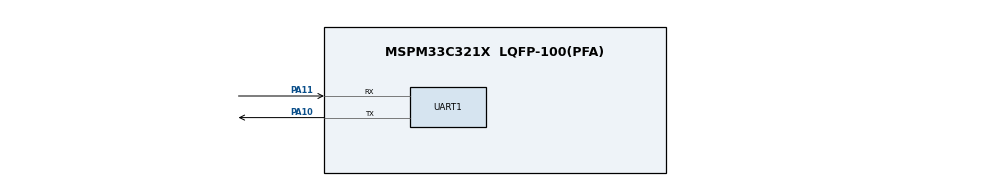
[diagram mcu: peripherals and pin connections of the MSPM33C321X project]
/**
 * @cliArgs --device "MSPM33C321X" --part "Default" --package "LQFP-100(PFA)" --product "mspm33_sdk@1.02.00.00"
 * @versions {"tool":"1.26.0+4407"}
 */
// @cliArgs --board /ti/boards/LP_MSPM33C321A --rtos nortos

/**
 * Import the modules used in this configuration.
 */
const Board  = scripting.addModule("/ti/driverlib/Board");
const SYSCTL = scripting.addModule("/ti/driverlib/SYSCTL");
const UART   = scripting.addModule("/ti/driverlib/UART", {}, false);
const UART1  = UART.addInstance();

/**
 * Write custom configuration values to the imported modules.
 */

SYSCTL.SYSPLL_CLK0En  = true;
SYSCTL.MCLKSource     = "HSCLK";
SYSCTL.SYSPLL_CLK0Div = 1;
SYSCTL.SYSPLL_Pdiv    = 4;
SYSCTL.SYSPLL_Qdiv    = 80;

UART1.$name                    = "UART_0";
UART1.targetBaudRate           = 115200;
UART1.enabledInterrupts        = ["EOT_DONE","RX"];
UART1.peripheral.$assign       = "UC1_0";
UART1.peripheral.rxPin.$assign = "PA11";
UART1.peripheral.txPin.$assign = "PA10";
UART1.txPinConfig.$name        = "ti_driverlib_gpio_GPIOPinGeneric0";
UART1.rxPinConfig.$name        = "ti_driverlib_gpio_GPIOPinGeneric1";

const ProjectConfig              = scripting.addModule("/ti/project_config/ProjectConfig", {}, false);
ProjectConfig.migrationCondition = true;

/**
 * Pinmux solution for unlocked pins/peripherals. This ensures that minor changes to the automatic solver in a future
 * version of the tool will not impact the pinmux you originally saw.  These lines can be completely deleted in order to
 * re-solve from scratch.
 */
Board.peripheral.$suggestSolution          = "DEBUGSS";
Board.peripheral.swclkPin.$suggestSolution = "PA20";
Board.peripheral.swdioPin.$suggestSolution = "PA19";
SYSCTL.peripheral.$suggestSolution         = "SYSCTL";
